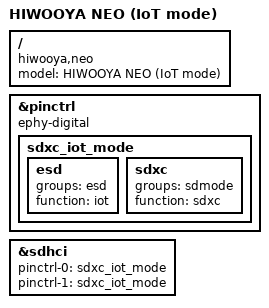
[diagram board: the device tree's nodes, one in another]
#include "mt7628an_hiwooya.dtsi"

/ {
        compatible = "hiwooya,neo", "hiwooya,neo-iot", "mediatek,mt7628an-soc";
        model = "HIWOOYA NEO (IoT mode)";
};

&pinctrl {
	ephy-digital;

	sdxc_iot_mode: sdxc_iot_mode {
		esd {
			groups = "esd";
			function = "iot";
		};

		sdxc {
			groups = "sdmode";
			function = "sdxc";
		};
	};
};

&sdhci {
	status = "okay";

	pinctrl-0 = <&sdxc_iot_mode>;
	pinctrl-1 = <&sdxc_iot_mode>;
};


